# TC37XPD register map
Vendor: Infineon; Series: ATVMC; File version: 100
CPU: other r0p0, little endian, MPU, FPU, vendor SysTick, 4 interrupt priority bits
Registers are 32-bit, read-write, reset 0x0 unless marked. A register's access mark holds for its fields unless they carry their own. Offsets are from the block's base; [hi:lo] are bit positions; {n}, {i} and the like mark numbered series; 'fields as' and 'values as' point back to an identical list.

## AMU00 — AMU
Base 0xF8508000
Same registers: AMU01 0xF8508100
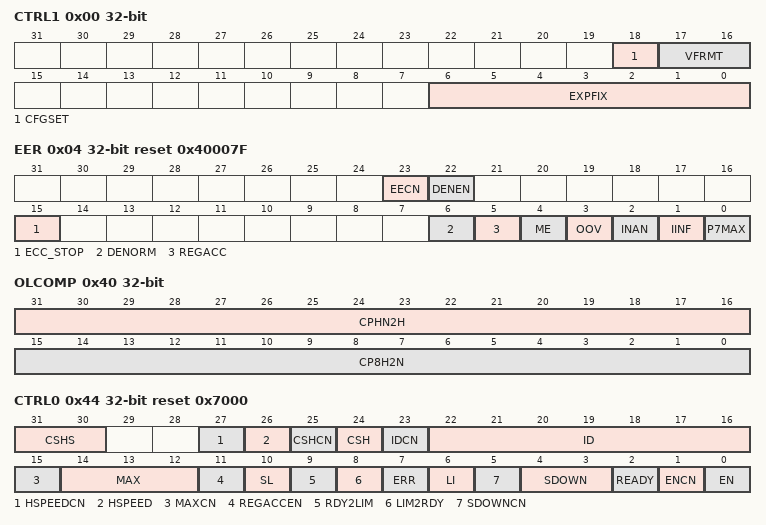
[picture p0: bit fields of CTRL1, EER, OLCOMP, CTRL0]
0x00 CTRL1 — Control Register 1 resetvalue={Application Reset:0x0}
  [18] CFGSET — Configuration Set CFGSET. When set to 1 z is initialised to p 5 . When set to 0 z is not initialised and returns whatever value is present in the register from previous operations.
  [17:16] VFRMT — Parameter Matrix V Format VFRMT. This field controls the storage format of parameter matrix V. It can have the following values
  [6:0] EXPFIX — Exponent for Fixed Exponent Format EXPFIX. This field stores the exponent to be used when V is stored in memory as a 16 bit fixed point value. See the related VFRMT field.
0x04 EER access per field reset 0x40007F — Error Enable Register resetvalue={Application Reset:0x40007F}
  [23] EECN wo — Enable Stop Condition Bit EECN. Must be written with 1 to allow the state of bit 22 to be changed
  [22] DENEN rw — Enable Stop on Input Denormalised Number Error. DENEN. Stop execution if a 32 bit input value contains a denormalised number
  [15] ECC_STOP ro — Stop on ECC Error ECC STOP. Enable the use of an ECC error detected during a read from a system memory to stop the AMU and flag an interrupt
  [6] DENORM rw — Enable Interrupt on Input Denormalised Number Error DENORM. Enable interrupt if a 32 bit input value contains a denormalised number
  [5] REGACC rw — Enable Interrupt on Register Access during Computation Error REGACC. This flag enables interrupt generation if registers are written during computation
  [4] ME rw — Enable Interrupt on Memory Error ME. Enable interrupt on memory error
  [3] OOV rw — Enable Interrupt on Output Overflow OOV. Enable interrupt if output overflows.
  [2] INAN rw — Enable Interrupt on Input NaN Error INAN. Enable interrupt if input value is not a number NaN
  [1] IINF rw — Enable Interrupt on Input Infinity Error IINF. Enable interrupt if input value is infinity
  [0] P7MAX rw — Enable Interrupt on P7 Over Maximum Error P7MAX. Enable interrupt on P7MAX error.
0x08 P10SINT — Parameter p10 Register resetvalue={Application Reset:0x0}
  [15:0] NCROSSING — Loop Counter Value to Raise Limit Interrupt NCROSSING. AMU will raise the limit interrupt if p8 is equal to or greater than this value.
0x0C P6SINT — Parameter p6 Register resetvalue={Application Reset:0x0}
  [15:0] NEND — Max Iteration Counter for Outer Loop NEND. This register contains the row dimension of matrix V. It is the maximum number of iterations of the outer loop of the algorithm.
0x10 P7SINT — Parameter p7 Register resetvalue={Application Reset:0x0}
  [15:0] M — Max Iteration Counter for Inner Loop M. This register contains the column dimension of matrix V. It is the maximum number of iterations of the inner loop of the algorithm. Due to hardware constraints this value cannot be larger than 32.
0x14 P8SINT — Parameter p8 Register resetvalue={Application Reset:0x0}
  [15:0] NSTART — Start Value for Outer Loop NSTART. This register should be programmed with the start value for the outer loop of the algorithm. For instructions to use please refer to the section about restarting AMU after an interrupted calculation.
0x18 P9DOUBLELOW32 — Parameter p9 Register resetvalue={Application Reset:0x0}
  [31:0] P9DOUBLE — AMU Parameter p9 Register Double P9DOUBLE. This bit field holds the lower 32 bit of parameter p9 of the algorithm.
0x1C P9DOUBLEHIGH32 — Parameter p9 Register resetvalue={Application Reset:0x0}
  [31:0] P9DOUBLE — AMU Parameter p9 Register Double P9DOUBLE. This bit field holds the higher 32 bit of parameter p9 of the algorithm.
0x20 VPFLOAT — Coefficient Matrix V Register resetvalue={Application Reset:0x0}
  [31:0] VPFLOAT — AMU V Parameter Register Pointer to Float VPFLOAT. This bit field holds the base address of the coefficient matrix V NxM
0x24 LPFLOAT — Coefficient Array L Register resetvalue={Application Reset:0x0}
  [31:0] LPFLOAT — AMU Coefficient Array L Pointer to Float LPFLOAT. This bit field holds a pointer to the coefficient array L M of the algorithm.
0x28 P1PFLOAT — Parameter p1 Register resetvalue={Application Reset:0x0}
  [31:0] P1PFLOAT — AMU P1 Parameter Register Pointer to Float P1PFLOAT. This bit field holds a pointer to the parameter array p1 M of the algorithm.
0x2C P2PFLOAT — Parameter p2 Register resetvalue={Application Reset:0x0}
  [31:0] P2PFLOAT — AMU P2 Parameter Register Pointer to Float P2PFLOAT. This bit field holds a pointer to the parameter array p2 M of the algorithm.
0x30 P3PFLOAT — Parameter p3 Register resetvalue={Application Reset:0x0}
  [31:0] P3PFLOAT — AMU P3 Parameter Register Pointer to Float P3PFLOAT. This bit field holds a pointer to the parameter array p3 N of the algorithm.
0x34 P4FLOAT — Parameter p4 Register resetvalue={Application Reset:0x0}
  [31:0] P4FLOAT — AMU P4 Parameter Register Float P4FLOAT. This bit field holds the parameter p4 of the algorithm.
0x38 P5FLOAT — Parameter p5 Register resetvalue={Application Reset:0x0}
  [31:0] P5FLOAT — AMU P5 Parameter Register Float P5FLOAT. This bit field holds the parameter p5 of the algorithm.
0x3C UPFLOAT — Input Vector u Register resetvalue={Application Reset:0x0}
  [31:0] UPFLOAT — AMU Input Vector Register Pointer to Float UPFLOAT. This bit field holds a pointer to the input vector array u M of the algorithm.
0x40 OLCOMP — Parameter p8 Register resetvalue={Application Reset:0x0}
  [31:16] CPHN2H — Trigger Value for switch from full to half speed CPHN2H. This register should be programmed with the p8 value when the AMU should switch from running at full programmed speed to half programmed speed. For instructions to use please refer to the section about current shaping.
  [15:0] CP8H2N — Trigger Value for switch from half to full speed CP8H2N. This register should be programmed with the p8 value when the AMU should switch from running at half programmed speed to full programmed speed. For instructions to use please refer to the section about current shaping.
0x44 CTRL0 access per field reset 0x7000 — Control Register 0 resetvalue={Application Reset:0x7000}
  [31:30] CSHS ro — Current Shaping Status CSHS
  [27] HSPEEDCN wo — Identifier Condition Bit HSPEEDCN. This bit must be written with 1 to change the ID field. If 0 is written the value written to the HSPEED field is ignored. Always read as 0 .
  [26] HSPEED rw — Half Speed HSPEED. This bit will switch the AMU core to run at a speed equivalent to SDOWN 1 when written with 1 . No effect if SDOWN is already at maximum permissible value of 11 .
  [25] CSHCN wo — Current Shaping Enable Condition Bit CSHCN. This bit must be written with 1 to change the CSH field. If 0 is written the value written to the CSH field is ignored. Always read as 0 .
  [24] CSH rw — Current Shaping Enable CSH. Write 1 to enable current shaping. See 8220 Current Shaping 8221 on Page 160 14 for information.
  [23] IDCN wo — Identifier Condition Bit IDCN. This bit must be written with 1 to change the ID field. If 0 is written the value written to the ID field is ignored. Always read as 0 .
  [22:16] ID rw — Identifier ID. This field is freely readable and writable. Use to identify specific calculation.
  [15] MAXCN wo — Maximum Speed Condition Bit MAXCN. This bit must be written with 1 to change the MAX bits. If 0 is written the value written to the MAX bits is ignored. Always read as 0 .
  [14:12] MAX rw — Maximum Speed Control MAX. The field is used to define the speed at which arithmetic operations complete. It can set the speed to between 1 clock cycle when written with 0 and 8 clock cycles when written with 7 .
  [11] REGACCEN rw — Allow Register Write when Active REGACCEN. If this flag is set writes to the P10SINT P6SINT and OLCOMP registers when the AMU is active do not cause an error.
  [10] SL rw — Stop on Limit Interrupt SL. If this flag is set AMU stops on limit interrupt
  [9] RDY2LIM rw — Ready to Limit Interrupt RDY2LIM. If this flag is set the ready interrupt is also signaled the limit interrupt line.
  [8] LIM2RDY rw — Limit to Ready Interrupt LIM2RDY. If this flag is set a limit interrupt is also signaled at the ready interrupt line.
  [7] ERR ro — Error Interrupt ERR. This flag signifies that an error during the computation has occurred. An interrupt is raised. Cleared by hardware when read or on the start of the next execution 0 to 1 transition on EN .
  [6] LI ro — Limit Interrupt LI. This flag shows the state of the limit interrupt. This interrupt is raised when the AMU outer loop counter reaches the value provided in p10. Cleared by hardware when read or on the start of the next execution 0 to 1 transition on EN .
  [5] SDOWNCN wo — Slowdown Condition Bit SDOWNCN. This bit must be written with 1 to change the SDOWN field. If 0 is written the value written to the SDOWN field is ignored. Always read as 0 .
  [4:3] SDOWN rw — Slowdown Flag SDOWN. The flags can be used to slow down the state machine which controls the algorithm.
  [2] READY ro — Ready Flag READY. This bit is cleared by hardware when a computation starts and set by hardware upon successful completion of the computation.
  [1] ENCN wo — Enable Condition Bit ENCN. This bit must be written with 1 to change the EN field. If 0 is written the value written to the EN field is ignored. Always read as 0 .
  [0] EN rw — Enable Bit EN. Write 1 to enable the algorithm. Write 0 to disable the algorithm. The flag will return a 1 if read while the algorithm is running and 0 is the algorithm is stopped or finished.
0x80 ZDOUBLELOW32 ro reset 0xFFFFFFFF — Return Value Register resetvalue={Application Reset:0x0FFFFFFFF}
  [31:0] ZDOUBLE — AMU Return value z Register Double ZDOUBLE. This bit field holds the lower 32 bit of return value z of the algorithm.
0x84 ZDOUBLEHIGH32 ro reset 0x7FFFFFFF — Return Value Register resetvalue={Application Reset:0x7FFFFFFF}
  [31:0] ZDOUBLE — AMU return value z Register Double ZDOUBLE. This bit field holds the higher 32 bit of return value z of the algorithm.
0x88 ZFLOAT ro reset 0x7FFFFFFF — Return Value Register resetvalue={Application Reset:0x7FFFFFFF}
  [31:0] ZFLOAT — AMU Result Register Float ZFLOAT. This bit field holds the return value z of the algorithm.
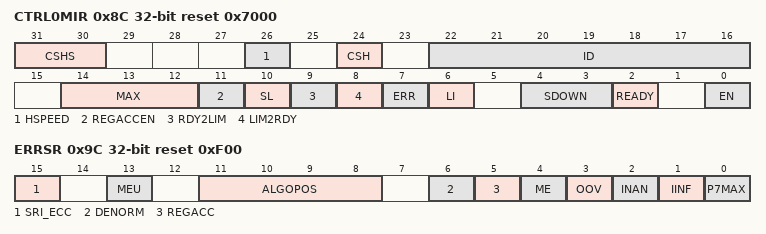
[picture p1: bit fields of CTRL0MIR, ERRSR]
0x8C CTRL0MIR ro reset 0x7000 — Control Register 0 Mirror resetvalue={Application Reset:0x7000}
  [31:30] CSHS — Current Shaping Status CSHS
  [26] HSPEED — Half Speed HSPEED. This bit will switch the AMU core to run at a speed equivalent to SDOWN 1 when written with 1 . No effect if SDOWN is already at maximum permissible value of 11 .
  [24] CSH — Current Shaping Enable CSH. Write 1 to enable current shaping. See ok for information.
  [22:16] ID — Identifier ID. Used to identify a specific calculation.
  [14:12] MAX — Maximum Speed Control MAX. The field is used to report the speed at which arithmetic operations complete. The speed varies between 1 clock cycle when 0 and 8 clock cycles when 7 .
  [11] REGACCEN — Allow Register Write when Active REGACCEN. If this flag is set writes to the P10SINT P6SINTand OLCOMP registers when the AMU is active do not cause an error.
  [10] SL — Stop on Limit Interrupt SL. If this flag is set AMU stops on limit interrupt
  [9] RDY2LIM — Ready to Limit Interrupt RDY2LIM. If this flag is set the ready interrupt is also signaled the limit interrupt line.
  [8] LIM2RDY — Limit to Ready Interrupt LIM2RDY. If this flag is set a limit interrupt is also signaled at the ready interrupt line.
  [7] ERR — Error Interrupt ERR. This flag signifies that an error during the computation has occurred. An interrupt is raised.
  [6] LI — Limit Interrupt LI. This flag controls the state of the limit interrupt. This interrupt is raised when the AMU outer loop counter reaches the value provided in p10.
  [4:3] SDOWN — Slowdown Flag SDOWN. This flag reports the speed of the state machine which controls the algorithm.
  [2] READY — Ready Flag READY. This bit is set by hardware upon successful completion of the computation.
  [0] EN — Enable Bit EN. The flag is set if the module is running.
0x90 YDOUBLELOW32 ro reset 0xFFFFFFFF — Intermediate Result yRegister resetvalue={Application Reset:0x0FFFFFFFF}
  [31:0] YDOUBLE — AMU v Result Register Double YDOUBLE. This bit field holds the lower 32 bit of intermediate value y of the algorithm.
0x94 YDOUBLEHIGH32 ro reset 0x7FFFFFFF — Intermediate Result yRegister resetvalue={Application Reset:0x7FFFFFFF}
  [31:0] YDOUBLE — AMU v Result Register Double YDOUBLE. This bit field holds the higher 32 bit of intermediate value yof the algorithm.
0x98 YFLOAT ro reset 0x7FFFFFFF — Intermediate Result y Float Register resetvalue={Application Reset:0x7FFFFFFF}
  [31:0] YFLOAT — AMU v Result Register Float YFLOAT. This bit field holds the intermediate value v of the algorithm.
0x9C ERRSR ro reset 0xF00 — Error Status Register resetvalue={Application Reset:0x0F00}
  [15] SRI_ECC — Uncorrectable Memory Error SRI ECC. A memory error has occurred when accessing a system memory resource
  [13] MEU — Uncorrectable Memory Error MEU. A memory error has occurred which could not be corrected by the ECC logic
  [11:8] ALGOPOS — Algorithm Position ALGOPOS. This bit field shows the state of the AMU state machine when the error occurs. This allows inferring the error cause. Coding see CROSSREFERENCE .
  [6] DENORM — Input Denormalised Number Error DENORM. A 32 bit input value contains a denormalised number
  [5] REGACC — Register Access during Computation Error REGACC. This error occurs when the AMU parameter registers are being written while the computation is being performed using these parameters.
  [4] ME — Memory Error ME. This error flag is generated by the DMA move engine. An error has occurred while accessing the memory.
  [3] OOV — Output Overflow OOV. An overflow occurred during computation. The output will be infinite or NaN.
  [2] INAN — Input NaN Error INAN. Input value is not a number NaN
  [1] IINF — Input Infinity Error IINF. Input value is infinity
  [0] P7MAX — P7 Over Maximum Error P7MAX. The value p7 is larger than supported by hardware. The maximum supported value is 32.
0xA0 P8SINTMIR ro — Interrupt Status Register resetvalue={Application Reset:0x0}
  [15:0] NSTART — Start Value for Outer Loop NSTART. Mirror of P8SINT field NSTART.
0xA8 UCURRPFLOAT ro — Current Input Vector Pointer Register resetvalue={Application Reset:0x0}
  fields as UPFLOAT
0xAC P1CURRPFLOAT ro — Current Parameter p1 Pointer Register resetvalue={Application Reset:0x0}
  [31:0] P1PFLOAT — AMU Input Vector Register Pointer to Float P1PFLOAT. This bit field holds a pointer to the input vector array p1 M of the algorithm.
0xB0 P2CURRPFLOAT ro — Current Parameter p2 Pointer Register resetvalue={Application Reset:0x0}
  [31:0] P2PFLOAT — AMU Input Vector Register Pointer to Float P2PFLOAT. This bit field holds a pointer to the input vector array p2 M of the algorithm.
0xB4 P3CURRPFLOAT ro — Current Parameter p3 Pointer Register resetvalue={Application Reset:0x0}
  [31:0] P3PFLOAT — AMU Input Vector Register Pointer to Float P3PFLOAT. This bit field holds a pointer to the input vector array p3 M of the algorithm.
0xB8 VCURRPFLOAT ro — Current Coefficient Matrix V Pointer Register resetvalue={Application Reset:0x0}
  [31:0] VPFLOAT — AMU V Coefficient Register Pointer to Float VPFLOAT. This bit field holds a pointer to the coefficient vector array V N M of the algorithm.
0xBC LCURRPFLOAT ro — Current Coefficient Matrix L Pointer Register resetvalue={Application Reset:0x0}
  [31:0] LPFLOAT — AMU Coefficient Register Pointer to Float LPFLOAT. This bit field holds a pointer to the coefficient array L M of the algorithm.
